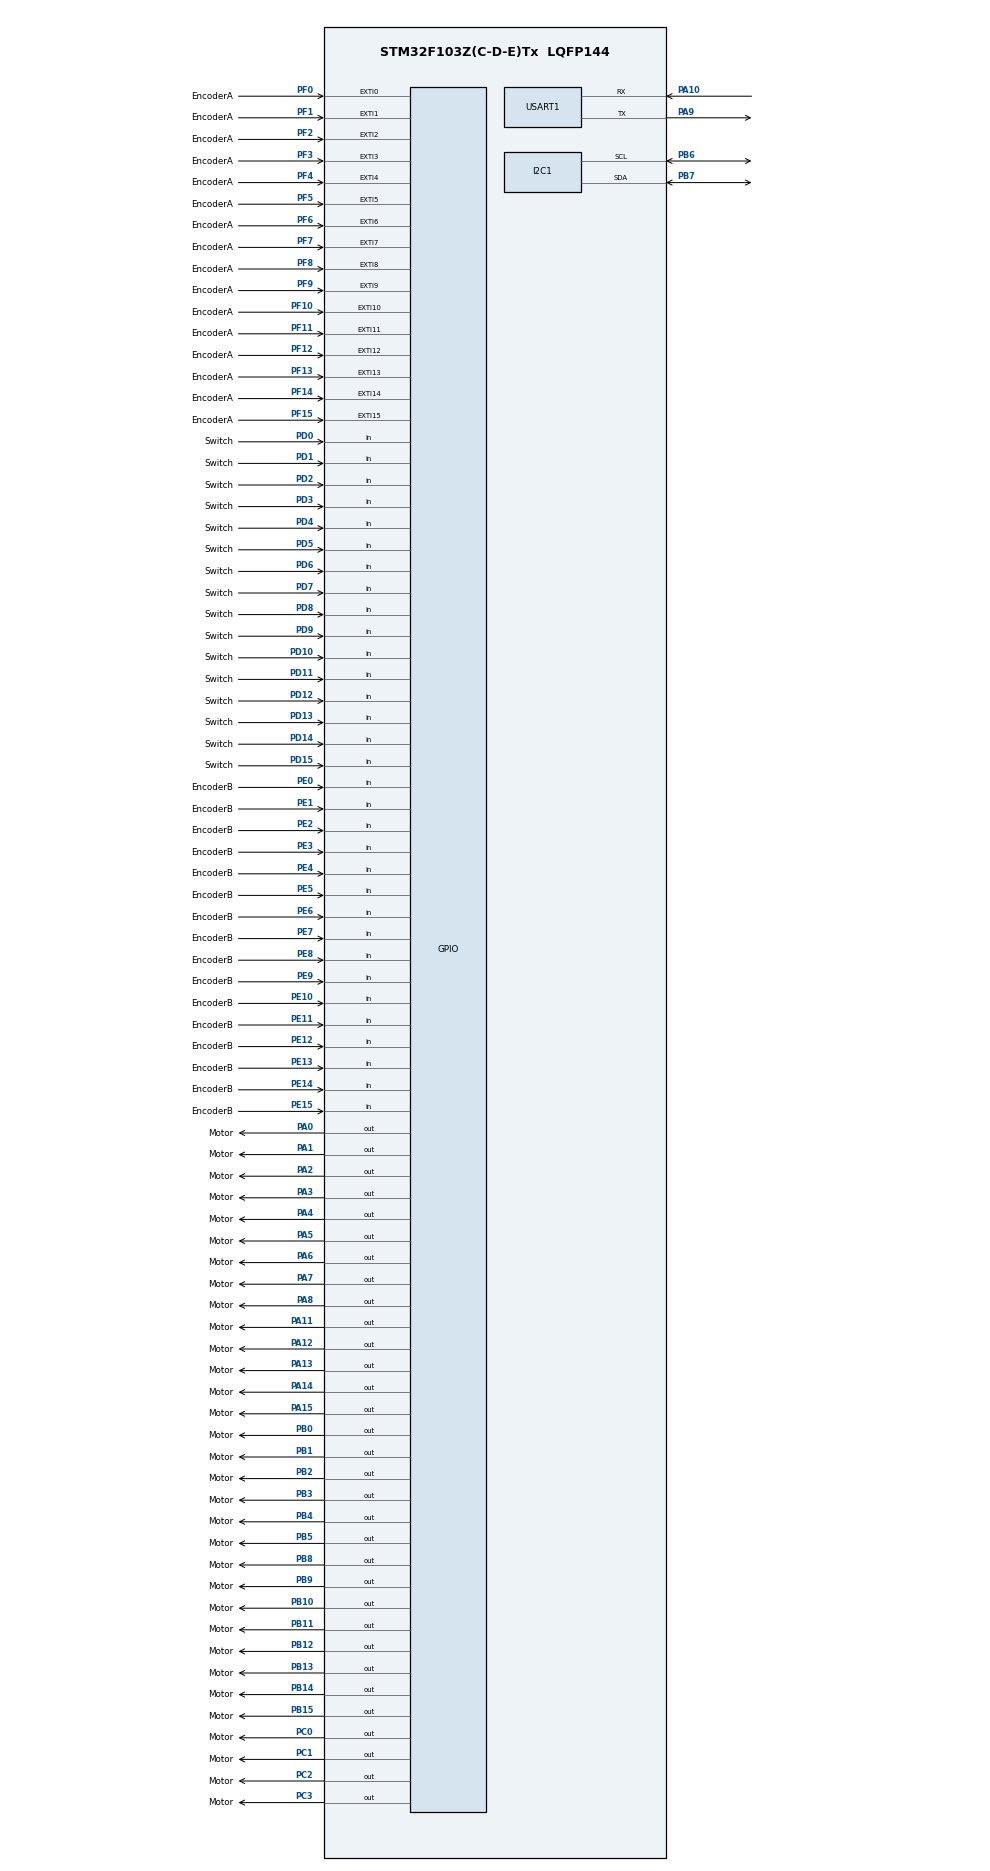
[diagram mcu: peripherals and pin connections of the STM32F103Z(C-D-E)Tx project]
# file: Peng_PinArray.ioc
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I2C1.I2C_Mode=I2C_Standard
Mcu.Family=STM32F1
Mcu.Name=STM32F103Z(C-D-E)Tx
Mcu.Package=LQFP144
NVIC.EXTI0_IRQn=true\:0\:0\:false\:false\:true\:true\:true\:true
NVIC.EXTI15_10_IRQn=true\:0\:0\:false\:false\:true\:true\:true\:true
NVIC.EXTI1_IRQn=true\:0\:0\:false\:false\:true\:true\:true\:true
NVIC.EXTI2_IRQn=true\:0\:0\:false\:false\:true\:true\:true\:true
NVIC.EXTI3_IRQn=true\:0\:0\:false\:false\:true\:true\:true\:true
NVIC.EXTI4_IRQn=true\:0\:0\:false\:false\:true\:true\:true\:true
NVIC.EXTI9_5_IRQn=true\:0\:0\:false\:false\:true\:true\:true\:true
NVIC.FLASH_IRQn=true\:0\:0\:false\:false\:true\:true\:true\:true
NVIC.I2C1_EV_IRQn=true\:0\:0\:false\:false\:true\:true\:true\:true
NVIC.PVD_IRQn=true\:0\:0\:false\:false\:true\:true\:true\:true
NVIC.PriorityGroup=NVIC_PRIORITYGROUP_4
NVIC.RCC_IRQn=true\:0\:0\:false\:false\:true\:true\:false\:true
NVIC.USART1_IRQn=true\:0\:0\:false\:false\:true\:true\:true\:true
PA0-WKUP.GPIO_Label=Motor
PA0-WKUP.GPIO_Speed=GPIO_SPEED_FREQ_LOW
PA0-WKUP.PinState=GPIO_PIN_SET
PA0-WKUP.Signal=GPIO_Output
PA1.GPIO_Label=Motor
PA1.GPIO_Speed=GPIO_SPEED_FREQ_LOW
PA1.PinState=GPIO_PIN_SET
PA1.Signal=GPIO_Output
PA10.Mode=Asynchronous
PA10.Signal=USART1_RX
PA11.GPIO_Label=Motor
PA11.GPIO_Speed=GPIO_SPEED_FREQ_LOW
PA11.PinState=GPIO_PIN_SET
PA11.Signal=GPIO_Output
PA12.GPIO_Label=Motor
PA12.GPIO_Speed=GPIO_SPEED_FREQ_LOW
PA12.PinState=GPIO_PIN_SET
PA12.Signal=GPIO_Output
PA13.GPIO_Label=Motor
PA13.GPIO_Speed=GPIO_SPEED_FREQ_LOW
PA13.PinState=GPIO_PIN_SET
PA13.Signal=GPIO_Output
PA14.GPIO_Label=Motor
PA14.GPIO_Speed=GPIO_SPEED_FREQ_LOW
PA14.PinState=GPIO_PIN_SET
PA14.Signal=GPIO_Output
PA15.GPIO_Label=Motor
PA15.GPIO_Speed=GPIO_SPEED_FREQ_LOW
PA15.PinState=GPIO_PIN_SET
PA15.Signal=GPIO_Output
PA2.GPIO_Label=Motor
PA2.GPIO_Speed=GPIO_SPEED_FREQ_LOW
PA2.PinState=GPIO_PIN_SET
PA2.Signal=GPIO_Output
PA3.GPIO_Label=Motor
PA3.GPIO_Speed=GPIO_SPEED_FREQ_LOW
PA3.PinState=GPIO_PIN_SET
PA3.Signal=GPIO_Output
PA4.GPIO_Label=Motor
PA4.GPIO_Speed=GPIO_SPEED_FREQ_LOW
PA4.PinState=GPIO_PIN_SET
PA4.Signal=GPIO_Output
PA5.GPIO_Label=Motor
PA5.GPIO_Speed=GPIO_SPEED_FREQ_LOW
PA5.PinState=GPIO_PIN_SET
PA5.Signal=GPIO_Output
PA6.GPIO_Label=Motor
PA6.GPIO_Speed=GPIO_SPEED_FREQ_LOW
PA6.PinState=GPIO_PIN_SET
PA6.Signal=GPIO_Output
PA7.GPIO_Label=Motor
PA7.GPIO_Speed=GPIO_SPEED_FREQ_LOW
PA7.PinState=GPIO_PIN_SET
PA7.Signal=GPIO_Output
PA8.GPIO_Label=Motor
PA8.GPIO_Speed=GPIO_SPEED_FREQ_LOW
PA8.PinState=GPIO_PIN_SET
PA8.Signal=GPIO_Output
PA9.Mode=Asynchronous
PA9.Signal=USART1_TX
PB0.GPIO_Label=Motor
PB0.PinState=GPIO_PIN_SET
PB0.Signal=GPIO_Output
PB1.GPIO_Label=Motor
PB1.PinState=GPIO_PIN_SET
PB1.Signal=GPIO_Output
PB10.GPIO_Label=Motor
PB10.PinState=GPIO_PIN_SET
PB10.Signal=GPIO_Output
PB11.GPIO_Label=Motor
PB11.PinState=GPIO_PIN_SET
PB11.Signal=GPIO_Output
PB12.GPIO_Label=Motor
PB12.PinState=GPIO_PIN_SET
PB12.Signal=GPIO_Output
PB13.GPIO_Label=Motor
PB13.PinState=GPIO_PIN_SET
PB13.Signal=GPIO_Output
PB14.GPIO_Label=Motor
PB14.PinState=GPIO_PIN_SET
PB14.Signal=GPIO_Output
PB15.GPIO_Label=Motor
PB15.PinState=GPIO_PIN_SET
PB15.Signal=GPIO_Output
PB2.GPIO_Label=Motor
PB2.PinState=GPIO_PIN_SET
PB2.Signal=GPIO_Output
PB3.GPIO_Label=Motor
PB3.PinState=GPIO_PIN_SET
PB3.Signal=GPIO_Output
PB4.GPIO_Label=Motor
PB4.PinState=GPIO_PIN_SET
PB4.Signal=GPIO_Output
PB5.GPIO_Label=Motor
PB5.PinState=GPIO_PIN_SET
PB5.Signal=GPIO_Output
PB6.Mode=I2C
PB6.Signal=I2C1_SCL
PB7.Mode=I2C
PB7.Signal=I2C1_SDA
PB8.GPIO_Label=Motor
PB8.PinState=GPIO_PIN_SET
PB8.Signal=GPIO_Output
PB9.GPIO_Label=Motor
PB9.PinState=GPIO_PIN_SET
PB9.Signal=GPIO_Output
PC0.GPIO_Label=Motor
PC0.PinState=GPIO_PIN_SET
PC0.Signal=GPIO_Output
PC1.GPIO_Label=Motor
PC1.PinState=GPIO_PIN_SET
PC1.Signal=GPIO_Output
PC2.GPIO_Label=Motor
PC2.PinState=GPIO_PIN_SET
PC2.Signal=GPIO_Output
PC3.GPIO_Label=Motor
PC3.PinState=GPIO_PIN_SET
PC3.Signal=GPIO_Output
PD0.GPIO_Label=Switch
PD0.GPIO_Mode=GPIO_MODE_INPUT
PD0.GPIO_PuPd=GPIO_NOPULL
PD0.Signal=GPIO_Input
PD1.GPIO_Label=Switch
PD1.GPIO_Mode=GPIO_MODE_INPUT
PD1.GPIO_PuPd=GPIO_NOPULL
PD1.Signal=GPIO_Input
PD10.GPIO_Label=Switch
PD10.GPIO_Mode=GPIO_MODE_INPUT
PD10.GPIO_PuPd=GPIO_NOPULL
PD10.Signal=GPIO_Input
PD11.GPIO_Label=Switch
PD11.GPIO_Mode=GPIO_MODE_INPUT
PD11.GPIO_PuPd=GPIO_NOPULL
PD11.Signal=GPIO_Input
PD12.GPIO_Label=Switch
PD12.GPIO_Mode=GPIO_MODE_INPUT
PD12.GPIO_PuPd=GPIO_NOPULL
PD12.Signal=GPIO_Input
PD13.GPIO_Label=Switch
PD13.GPIO_Mode=GPIO_MODE_INPUT
PD13.GPIO_PuPd=GPIO_NOPULL
PD13.Signal=GPIO_Input
PD14.GPIO_Label=Switch
PD14.GPIO_Mode=GPIO_MODE_INPUT
PD14.GPIO_PuPd=GPIO_NOPULL
PD14.Signal=GPIO_Input
PD15.GPIO_Label=Switch
PD15.GPIO_Mode=GPIO_MODE_INPUT
PD15.GPIO_PuPd=GPIO_NOPULL
PD15.Signal=GPIO_Input
PD2.GPIO_Label=Switch
PD2.GPIO_Mode=GPIO_MODE_INPUT
PD2.GPIO_PuPd=GPIO_NOPULL
PD2.Signal=GPIO_Input
PD3.GPIO_Label=Switch
PD3.GPIO_Mode=GPIO_MODE_INPUT
PD3.GPIO_PuPd=GPIO_NOPULL
PD3.Signal=GPIO_Input
PD4.GPIO_Label=Switch
PD4.GPIO_Mode=GPIO_MODE_INPUT
PD4.GPIO_PuPd=GPIO_NOPULL
PD4.Signal=GPIO_Input
PD5.GPIO_Label=Switch
PD5.GPIO_Mode=GPIO_MODE_INPUT
PD5.GPIO_PuPd=GPIO_NOPULL
PD5.Signal=GPIO_Input
PD6.GPIO_Label=Switch
PD6.GPIO_Mode=GPIO_MODE_INPUT
PD6.GPIO_PuPd=GPIO_NOPULL
PD6.Signal=GPIO_Input
PD7.GPIO_Label=Switch
PD7.GPIO_Mode=GPIO_MODE_INPUT
PD7.GPIO_PuPd=GPIO_NOPULL
PD7.Signal=GPIO_Input
PD8.GPIO_Label=Switch
PD8.GPIO_Mode=GPIO_MODE_INPUT
PD8.GPIO_PuPd=GPIO_NOPULL
PD8.Signal=GPIO_Input
PD9.GPIO_Label=Switch
PD9.GPIO_Mode=GPIO_MODE_INPUT
PD9.GPIO_PuPd=GPIO_NOPULL
PD9.Signal=GPIO_Input
PE0.GPIO_Label=EncoderB
PE0.GPIO_Mode=GPIO_MODE_INPUT
PE0.GPIO_PuPd=GPIO_NOPULL
PE0.Signal=GPIO_Input
PE1.GPIO_Label=EncoderB
PE1.GPIO_Mode=GPIO_MODE_INPUT
PE1.GPIO_PuPd=GPIO_NOPULL
PE1.Signal=GPIO_Input
PE10.GPIO_Label=EncoderB
PE10.GPIO_Mode=GPIO_MODE_INPUT
PE10.GPIO_PuPd=GPIO_NOPULL
PE10.Signal=GPIO_Input
PE11.GPIO_Label=EncoderB
PE11.GPIO_Mode=GPIO_MODE_INPUT
PE11.GPIO_PuPd=GPIO_NOPULL
PE11.Signal=GPIO_Input
PE12.GPIO_Label=EncoderB
PE12.GPIO_Mode=GPIO_MODE_INPUT
PE12.GPIO_PuPd=GPIO_NOPULL
PE12.Signal=GPIO_Input
PE13.GPIO_Label=EncoderB
PE13.GPIO_Mode=GPIO_MODE_INPUT
PE13.GPIO_PuPd=GPIO_NOPULL
PE13.Signal=GPIO_Input
PE14.GPIO_Label=EncoderB
PE14.GPIO_Mode=GPIO_MODE_INPUT
PE14.GPIO_PuPd=GPIO_NOPULL
PE14.Signal=GPIO_Input
PE15.GPIO_Label=EncoderB
PE15.GPIO_Mode=GPIO_MODE_INPUT
PE15.GPIO_PuPd=GPIO_NOPULL
PE15.Signal=GPIO_Input
PE2.GPIO_Label=EncoderB
PE2.GPIO_Mode=GPIO_MODE_INPUT
PE2.GPIO_PuPd=GPIO_NOPULL
PE2.Signal=GPIO_Input
PE3.GPIO_Label=EncoderB
PE3.GPIO_Mode=GPIO_MODE_INPUT
PE3.GPIO_PuPd=GPIO_NOPULL
PE3.Signal=GPIO_Input
PE4.GPIO_Label=EncoderB
PE4.GPIO_Mode=GPIO_MODE_INPUT
PE4.GPIO_PuPd=GPIO_NOPULL
PE4.Signal=GPIO_Input
PE5.GPIO_Label=EncoderB
PE5.GPIO_Mode=GPIO_MODE_INPUT
PE5.GPIO_PuPd=GPIO_NOPULL
PE5.Signal=GPIO_Input
PE6.GPIO_Label=EncoderB
PE6.GPIO_Mode=GPIO_MODE_INPUT
PE6.GPIO_PuPd=GPIO_NOPULL
PE6.Signal=GPIO_Input
PE7.GPIO_Label=EncoderB
PE7.GPIO_Mode=GPIO_MODE_INPUT
PE7.GPIO_PuPd=GPIO_NOPULL
PE7.Signal=GPIO_Input
PE8.GPIO_Label=EncoderB
PE8.GPIO_Mode=GPIO_MODE_INPUT
PE8.GPIO_PuPd=GPIO_NOPULL
PE8.Signal=GPIO_Input
PE9.GPIO_Label=EncoderB
PE9.GPIO_Mode=GPIO_MODE_INPUT
PE9.GPIO_PuPd=GPIO_NOPULL
PE9.Signal=GPIO_Input
PF0.GPIO_Label=EncoderA
PF0.GPIO_ModeDefaultEXTI=GPIO_MODE_IT_RISING
PF0.GPIO_PuPd=GPIO_NOPULL
PF0.Signal=GPXTI0
PF1.GPIO_Label=EncoderA
PF1.GPIO_ModeDefaultEXTI=GPIO_MODE_IT_RISING
PF1.GPIO_PuPd=GPIO_NOPULL
PF1.Signal=GPXTI1
PF10.GPIO_Label=EncoderA
PF10.GPIO_ModeDefaultEXTI=GPIO_MODE_IT_RISING
PF10.GPIO_PuPd=GPIO_NOPULL
PF10.Signal=GPXTI10
PF11.GPIO_Label=EncoderA
PF11.GPIO_ModeDefaultEXTI=GPIO_MODE_IT_RISING
PF11.GPIO_PuPd=GPIO_NOPULL
PF11.Signal=GPXTI11
PF12.GPIO_Label=EncoderA
PF12.GPIO_ModeDefaultEXTI=GPIO_MODE_IT_RISING
PF12.GPIO_PuPd=GPIO_NOPULL
PF12.Signal=GPXTI12
PF13.GPIO_Label=EncoderA
PF13.GPIO_ModeDefaultEXTI=GPIO_MODE_IT_RISING
PF13.GPIO_PuPd=GPIO_NOPULL
PF13.Signal=GPXTI13
PF14.GPIO_Label=EncoderA
PF14.GPIO_ModeDefaultEXTI=GPIO_MODE_IT_RISING
PF14.GPIO_PuPd=GPIO_NOPULL
PF14.Signal=GPXTI14
PF15.GPIO_Label=EncoderA
PF15.Signal=GPXTI15
PF2.GPIO_Label=EncoderA
PF2.GPIO_ModeDefaultEXTI=GPIO_MODE_IT_RISING
PF2.GPIO_PuPd=GPIO_NOPULL
PF2.Signal=GPXTI2
PF3.GPIO_Label=EncoderA
PF3.Signal=GPXTI3
PF4.GPIO_Label=EncoderA
PF4.GPIO_ModeDefaultEXTI=GPIO_MODE_IT_RISING
PF4.GPIO_PuPd=GPIO_NOPULL
PF4.Signal=GPXTI4
PF5.GPIO_Label=EncoderA
PF5.GPIO_ModeDefaultEXTI=GPIO_MODE_IT_RISING
PF5.GPIO_PuPd=GPIO_NOPULL
PF5.Signal=GPXTI5
PF6.GPIO_Label=EncoderA
PF6.GPIO_ModeDefaultEXTI=GPIO_MODE_IT_RISING
PF6.GPIO_PuPd=GPIO_NOPULL
PF6.Signal=GPXTI6
PF7.GPIO_Label=EncoderA
PF7.GPIO_ModeDefaultEXTI=GPIO_MODE_IT_RISING
PF7.GPIO_PuPd=GPIO_NOPULL
PF7.Signal=GPXTI7
PF8.GPIO_Label=EncoderA
PF8.GPIO_ModeDefaultEXTI=GPIO_MODE_IT_RISING
PF8.GPIO_PuPd=GPIO_NOPULL
PF8.Signal=GPXTI8
PF9.GPIO_Label=EncoderA
PF9.GPIO_ModeDefaultEXTI=GPIO_MODE_IT_RISING
PF9.GPIO_PuPd=GPIO_NOPULL
PF9.Signal=GPXTI9
ProjectManager.HeapSize=0x200
ProjectManager.StackSize=0x400
ProjectManager.TargetToolchain=MDK-ARM V5.32
RCC.APB1Freq_Value=8000000
RCC.APB2Freq_Value=8000000
USART1.VirtualMode=VM_ASYNC
VP_SYS_VS_ND.Mode=No_Debug
board=custom

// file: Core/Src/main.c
/* USER CODE BEGIN Header */
/**
  ******************************************************************************
  * @file           : main.c
  * @brief          : Main program body
  ******************************************************************************
  * @attention
  *
  * Copyright (c) 2023 STMicroelectronics.
  * All rights reserved.
  *
  * This software is licensed under terms that can be found in the LICENSE file
  * in the root directory of this software component.
  * If no LICENSE file comes with this software, it is provided AS-IS.
  *
  ******************************************************************************
  */
/* USER CODE END Header */
#include "main.h"
#include "i2c.h"
#include "usart.h"
#include "gpio.h"

/* USER CODE BEGIN Includes */
#include "math.h"
#include "Control.h"
#include "Communication.h"
/* USER CODE END Includes */

/* USER CODE BEGIN PD */
extern Motor Motors[16];
/* USER CODE END PD */

void SystemClock_Config(void);

/* USER CODE BEGIN 0 */
void EncoderCount(uint16_t pin);
int GetPin(uint16_t pin);
/* USER CODE END 0 */

int main(void)
{

  /* MCU Configuration--------------------------------------------------------*/

  /* Reset of all peripherals, Initializes the Flash interface and the Systick. */
  HAL_Init();

  /* Configure the system clock */
  SystemClock_Config();

  /* Initialize all configured peripherals */
  MX_GPIO_Init();
  MX_USART1_UART_Init();
  MX_I2C1_Init();
  /* USER CODE BEGIN 2 */
  Motor_Init(Motors);
	HAL_UART_Receive_IT(&huart1, &RxData, 1);
  /* USER CODE END 2 */

  /* Infinite loop */
  /* USER CODE BEGIN WHILE */
  while (1)
  {
    for(int i = 0; i < 16; i++)
    {
      Motors[i].Play(&Motors[i]);
    }
    /* USER CODE END WHILE */

  }
}

void SystemClock_Config(void)
{
  RCC_OscInitTypeDef RCC_OscInitStruct = {0};
  RCC_ClkInitTypeDef RCC_ClkInitStruct = {0};

  /** Initializes the RCC Oscillators according to the specified parameters
  * in the RCC_OscInitTypeDef structure.
  */
  RCC_OscInitStruct.OscillatorType = RCC_OSCILLATORTYPE_HSI;
  RCC_OscInitStruct.HSIState = RCC_HSI_ON;
  RCC_OscInitStruct.HSICalibrationValue = RCC_HSICALIBRATION_DEFAULT;
  RCC_OscInitStruct.PLL.PLLState = RCC_PLL_NONE;
  if (HAL_RCC_OscConfig(&RCC_OscInitStruct) != HAL_OK)
  {
    Error_Handler();
  }

  /** Initializes the CPU, AHB and APB buses clocks
  */
  RCC_ClkInitStruct.ClockType = RCC_CLOCKTYPE_HCLK|RCC_CLOCKTYPE_SYSCLK
                              |RCC_CLOCKTYPE_PCLK1|RCC_CLOCKTYPE_PCLK2;
  RCC_ClkInitStruct.SYSCLKSource = RCC_SYSCLKSOURCE_HSI;
  RCC_ClkInitStruct.AHBCLKDivider = RCC_SYSCLK_DIV1;
  RCC_ClkInitStruct.APB1CLKDivider = RCC_HCLK_DIV1;
  RCC_ClkInitStruct.APB2CLKDivider = RCC_HCLK_DIV1;

  if (HAL_RCC_ClockConfig(&RCC_ClkInitStruct, FLASH_LATENCY_0) != HAL_OK)
  {
    Error_Handler();
  }
}

/* USER CODE BEGIN 4 */
void HAL_GPIO_EXTI_Callback(uint16_t GPIO_Pin){
  EncoderCount(GPIO_Pin);
}

void EncoderCount(uint16_t pin){
  GPIO_PinState state = HAL_GPIO_ReadPin(GPIOE, pin);
	if(state == 1){
    Motors[GetPin(pin)].EncoderValue++;
  }else{
    Motors[GetPin(pin)].EncoderValue--;
  }
}

int GetPin(uint16_t pin){
  if(pin == GPIO_PIN_0){
    return 0;
  }else if(pin == GPIO_PIN_1){
    return 1;
  }else if(pin == GPIO_PIN_2){
    return 2;
  }else if(pin == GPIO_PIN_3){
    return 3;
  }else if(pin == GPIO_PIN_4){
    return 4;
  }else if(pin == GPIO_PIN_5){
    return 5;
  }else if(pin == GPIO_PIN_6){
    return 6;
  }else if(pin == GPIO_PIN_7){
    return 7;
  }else if(pin == GPIO_PIN_8){
    return 8;
  }else if(pin == GPIO_PIN_9){
    return 9;
  }else if(pin == GPIO_PIN_10){
    return 10;
  }else if(pin == GPIO_PIN_11){
    return 11;
  }else if(pin == GPIO_PIN_12){
    return 12;
  }else if(pin == GPIO_PIN_13){
    return 13;
  }else if(pin == GPIO_PIN_14){
    return 14;
  }else if(pin == GPIO_PIN_15){
    return 15;
  }
	return 16;
}

/* USER CODE END 4 */

void Error_Handler(void)
{
  __disable_irq();
  while (1)
  {
  }
}
